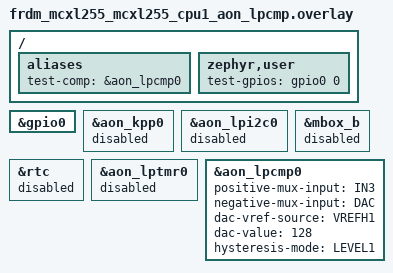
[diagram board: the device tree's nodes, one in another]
/*
 * Copyright 2026 NXP
 *
 * SPDX-License-Identifier: Apache-2.0
 */

#include <zephyr/dt-bindings/gpio/gpio.h>

/ {
	aliases {
		test-comp = &aon_lpcmp0;
	};

	zephyr,user {
		test-gpios = <&gpio0 0 GPIO_ACTIVE_HIGH>;
	};
};

&gpio0 {
	status = "okay";
};

&aon_kpp0 {
	status = "disabled";
};

&aon_lpi2c0 {
	status = "disabled";
};

&mbox_b {
	status = "disabled";
};

&rtc {
	status = "disabled";
};

&aon_lptmr0 {
	status = "disabled";
};

&aon_lpcmp0 {
	status = "okay";
	positive-mux-input = "IN3";
	negative-mux-input = "DAC";
	dac-vref-source = "VREFH1";
	dac-value = <128>;
	hysteresis-mode = "LEVEL1";
};
